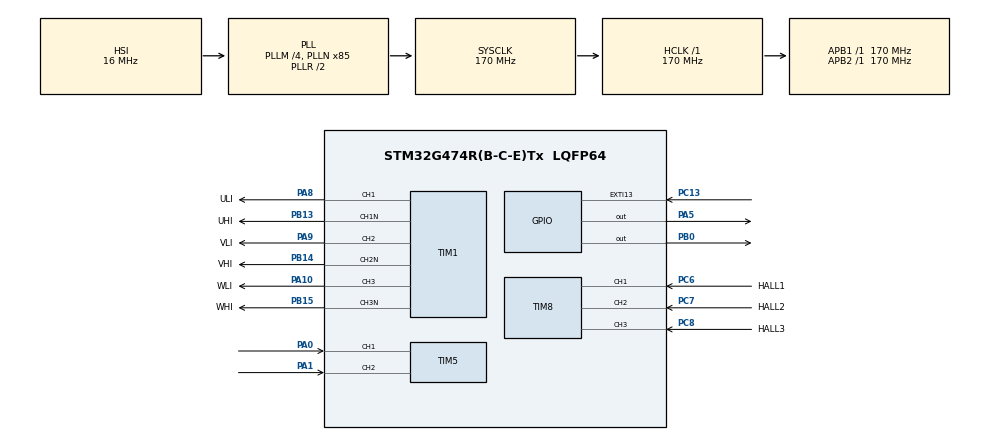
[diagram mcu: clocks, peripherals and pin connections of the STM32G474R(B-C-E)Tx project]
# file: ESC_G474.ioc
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Mcu.Family=STM32G4
Mcu.Name=STM32G474R(B-C-E)Tx
Mcu.Package=LQFP64
NUCLEO-G474RE.BUTTON=1
NUCLEO-G474RE.LD2=true
NUCLEO-G474RE.VCP=true
NVIC.EXTI15_10_IRQn=true\:0\:0\:false\:false\:true\:true\:true\:true
NVIC.PriorityGroup=NVIC_PRIORITYGROUP_4
NVIC.TIM1_BRK_TIM15_IRQn=true\:0\:0\:false\:false\:true\:true\:true\:true
NVIC.TIM1_UP_TIM16_IRQn=true\:0\:0\:false\:false\:true\:true\:true\:true
PA0.Signal=S_TIM5_CH1
PA1.Signal=S_TIM5_CH2
PA10.GPIO_Label=WLI
PA10.Signal=S_TIM1_CH3
PA13.GPIO_Label=T_SWDIO
PA13.Signal=SYS_JTMS-SWDIO
PA14.GPIO_Label=T_SWCLK
PA14.Signal=SYS_JTCK-SWCLK
PA2.Signal=LPUART1_TX
PA3.Signal=LPUART1_RX
PA5.Signal=GPIO_Output
PA8.GPIO_Label=ULI
PA8.Signal=S_TIM1_CH1
PA9.GPIO_Label=VLI
PA9.Signal=S_TIM1_CH2
PB0.Signal=GPIO_Output
PB13.GPIO_Label=UHI
PB13.Mode=PWM Generation1 CH1 CH1N
PB13.Signal=TIM1_CH1N
PB14.GPIO_Label=VHI
PB14.Mode=PWM Generation2 CH2 CH2N
PB14.Signal=TIM1_CH2N
PB15.GPIO_Label=WHI
PB15.Mode=PWM Generation3 CH3 CH3N
PB15.Signal=TIM1_CH3N
PB3.GPIO_Label=T_SWO
PB3.Signal=SYS_JTDO-SWO
PC13.Signal=GPXTI13
PC14-OSC32_IN.GPIO_Label=RCC_OSC32_IN
PC14-OSC32_IN.Signal=RCC_OSC32_IN
PC15-OSC32_OUT.GPIO_Label=RCC_OSC32_OUT
PC15-OSC32_OUT.Signal=RCC_OSC32_OUT
PC6.GPIO_Label=HALL1
PC6.Signal=S_TIM8_CH1
PC7.GPIO_Label=HALL2
PC7.Signal=S_TIM8_CH2
PC8.GPIO_Label=HALL3
PC8.Signal=S_TIM8_CH3
PF0-OSC_IN.GPIO_Label=RCC_OSC_IN
PF0-OSC_IN.Signal=RCC_OSC_IN
PF1-OSC_OUT.GPIO_Label=RCC_OSC_OUT
PF1-OSC_OUT.Signal=RCC_OSC_OUT
ProjectManager.HeapSize=0x200
ProjectManager.StackSize=0x400
ProjectManager.TargetToolchain=Makefile
RCC.ADC12Freq_Value=170000000
RCC.ADC345Freq_Value=170000000
RCC.AHBFreq_Value=170000000
RCC.APB1Freq_Value=170000000
RCC.APB1TimFreq_Value=170000000
RCC.APB2Freq_Value=170000000
RCC.APB2TimFreq_Value=170000000
RCC.CortexFreq_Value=170000000
RCC.EXTERNAL_CLOCK_VALUE=12288000
RCC.HCLKFreq_Value=170000000
RCC.HSE_VALUE=24000000
RCC.HSI48_VALUE=48000000
RCC.HSI_VALUE=16000000
RCC.LSE_VALUE=32768
RCC.PLLM=RCC_PLLM_DIV4
RCC.PLLN=85
RCC.RTCClockSelection=RCC_RTCCLKSOURCE_LSE
RCC.SYSCLKFreq_VALUE=170000000
RCC.SYSCLKSource=RCC_SYSCLKSOURCE_PLLCLK
RCC.USBFreq_Value=170000000
RCC.VCOOutputFreq_Value=340000000
SH.S_TIM1_CH1.0=TIM1_CH1,PWM Generation1 CH1 CH1N
SH.S_TIM1_CH2.0=TIM1_CH2,PWM Generation2 CH2 CH2N
SH.S_TIM1_CH3.0=TIM1_CH3,PWM Generation3 CH3 CH3N
SH.S_TIM5_CH1.0=TIM5_CH1,Encoder_Interface
SH.S_TIM5_CH2.0=TIM5_CH2,Encoder_Interface
SH.S_TIM8_CH1.0=TIM8_CH1,Xored_Inputs_Hall_Sensor_Interface
SH.S_TIM8_CH2.0=TIM8_CH2,Xored_Inputs_Hall_Sensor_Interface
SH.S_TIM8_CH3.0=TIM8_CH3,Xored_Inputs_Hall_Sensor_Interface
TIM1.BreakState=TIM_BREAK_ENABLE
TIM1.Channel-PWM\ Generation1\ CH1\ CH1N=TIM_CHANNEL_1
TIM1.Channel-PWM\ Generation2\ CH2\ CH2N=TIM_CHANNEL_2
TIM1.Channel-PWM\ Generation3\ CH3\ CH3N=TIM_CHANNEL_3
TIM1.CounterMode=TIM_COUNTERMODE_CENTERALIGNED1
TIM1.PulseNoDither_1=32768
TIM1.PulseNoDither_2=32768
TIM1.PulseNoDither_3=32768
TIM1.TIM_MasterOutputTrigger2=TIM_TRGO2_UPDATE
TIM1.TIM_MasterSlaveMode=TIM_MASTERSLAVEMODE_ENABLE
TIM6.Prescaler=107
VP_NUCLEO-G474RE_VS_BSP_COMMON.Mode=COMMON
VP_SYS_VS_DBSignals.Mode=DisableDeadBatterySignals
VP_TIM15_VS_ClockSourceINT.Mode=Internal
VP_TIM1_VS_ClockSourceINT.Mode=Internal
VP_TIM6_VS_ClockSourceINT.Mode=Enable_Timer
board=NUCLEO-G474RE

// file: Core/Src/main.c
/* USER CODE BEGIN Header */
/**
 ******************************************************************************
 * @file           : main.c
 * @brief          : Main program body
 ******************************************************************************
 * @attention
 *
 * Copyright (c) 2026 STMicroelectronics.
 * All rights reserved.
 *
 * This software is licensed under terms that can be found in the LICENSE file
 * in the root directory of this software component.
 * If no LICENSE file comes with this software, it is provided AS-IS.
 *
 ******************************************************************************
 */
/* USER CODE END Header */
#include "main.h"
#include "tim.h"
#include "gpio.h"

/* USER CODE BEGIN Includes */
#include "App.hpp"
/* USER CODE END Includes */

COM_InitTypeDef BspCOMInit;

void SystemClock_Config(void);

int main(void)
{

  /* MCU Configuration--------------------------------------------------------*/

  /* Reset of all peripherals, Initializes the Flash interface and the Systick. */
  HAL_Init();

  /* Configure the system clock */
  SystemClock_Config();

  /* Initialize all configured peripherals */
  MX_GPIO_Init();
  MX_TIM1_Init();
  MX_TIM8_Init();
  MX_TIM5_Init();
  MX_TIM6_Init();
  MX_TIM15_Init();
  /* USER CODE BEGIN 2 */

  // HAL_ADC_Start_DMA(&hadc1,Motor.MotorCurrents.ADC_VAL_PhaseCurrents,3);

  //UART_writeLine("SESC V3");
  App_Init();
  /* USER CODE END 2 */

  /* Initialize led */
  BSP_LED_Init(LED_GREEN);

  /* Initialize USER push-button, will be used to trigger an interrupt each time it's pressed.*/
  BSP_PB_Init(BUTTON_USER, BUTTON_MODE_EXTI);

  /* Initialize COM1 port (115200, 8 bits (7-bit data + 1 stop bit), no parity */
  BspCOMInit.BaudRate   = 115200;
  BspCOMInit.WordLength = COM_WORDLENGTH_8B;
  BspCOMInit.StopBits   = COM_STOPBITS_1;
  BspCOMInit.Parity     = COM_PARITY_NONE;
  BspCOMInit.HwFlowCtl  = COM_HWCONTROL_NONE;
  if (BSP_COM_Init(COM1, &BspCOMInit) != BSP_ERROR_NONE)
  {
    Error_Handler();
  }

  /* Infinite loop */
  while (1)
  {

    /* USER CODE BEGIN 3 */
    App_Process();
  }
  /* USER CODE END 3 */
}

void SystemClock_Config(void)
{
  RCC_OscInitTypeDef RCC_OscInitStruct = {0};
  RCC_ClkInitTypeDef RCC_ClkInitStruct = {0};

  /** Configure the main internal regulator output voltage
  */
  HAL_PWREx_ControlVoltageScaling(PWR_REGULATOR_VOLTAGE_SCALE1_BOOST);

  /** Initializes the RCC Oscillators according to the specified parameters
  * in the RCC_OscInitTypeDef structure.
  */
  RCC_OscInitStruct.OscillatorType = RCC_OSCILLATORTYPE_HSI;
  RCC_OscInitStruct.HSIState = RCC_HSI_ON;
  RCC_OscInitStruct.HSICalibrationValue = RCC_HSICALIBRATION_DEFAULT;
  RCC_OscInitStruct.PLL.PLLState = RCC_PLL_ON;
  RCC_OscInitStruct.PLL.PLLSource = RCC_PLLSOURCE_HSI;
  RCC_OscInitStruct.PLL.PLLM = RCC_PLLM_DIV4;
  RCC_OscInitStruct.PLL.PLLN = 85;
  RCC_OscInitStruct.PLL.PLLP = RCC_PLLP_DIV2;
  RCC_OscInitStruct.PLL.PLLQ = RCC_PLLQ_DIV2;
  RCC_OscInitStruct.PLL.PLLR = RCC_PLLR_DIV2;
  if (HAL_RCC_OscConfig(&RCC_OscInitStruct) != HAL_OK)
  {
    Error_Handler();
  }

  /** Initializes the CPU, AHB and APB buses clocks
  */
  RCC_ClkInitStruct.ClockType = RCC_CLOCKTYPE_HCLK|RCC_CLOCKTYPE_SYSCLK
                              |RCC_CLOCKTYPE_PCLK1|RCC_CLOCKTYPE_PCLK2;
  RCC_ClkInitStruct.SYSCLKSource = RCC_SYSCLKSOURCE_PLLCLK;
  RCC_ClkInitStruct.AHBCLKDivider = RCC_SYSCLK_DIV1;
  RCC_ClkInitStruct.APB1CLKDivider = RCC_HCLK_DIV1;
  RCC_ClkInitStruct.APB2CLKDivider = RCC_HCLK_DIV1;

  if (HAL_RCC_ClockConfig(&RCC_ClkInitStruct, FLASH_LATENCY_4) != HAL_OK)
  {
    Error_Handler();
  }
}

void Error_Handler(void)
{
  __disable_irq();
  while (1)
  {
  }
}
